# STM32H562 register map
File version: 0.1
CPU: CM33 r0p0, little endian, MPU, FPU, 4 interrupt priority bits
Registers are 32-bit, read-write, reset 0x0 unless marked. A register's access mark holds for its fields unless they carry their own. Offsets are from the block's base; [hi:lo] are bit positions; <NAME> marks a mode.

## SPI1 — Serial peripheral interface
Base 0x40013000
Same registers: SPI2 0x40003800, SPI3 0x40003C00, SPI4 0x40014C00, SPI6 0x40015000, SPI5 0x44002000, SEC_SPI2 0x50003800, SEC_SPI3 0x50003C00, SEC_SPI1 0x50013000, SEC_SPI4 0x50014C00, SEC_SPI6 0x50015000, SEC_SPI5 0x54002000
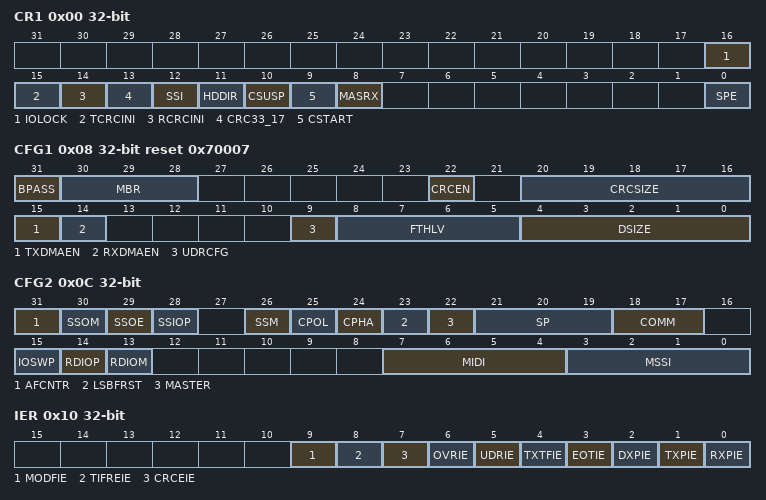
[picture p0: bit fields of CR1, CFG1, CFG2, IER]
0x00 CR1 access per field — SPI/I2S control register 1
  [16] IOLOCK rw — locking the AF configuration of associated IOs This bit is set by software and cleared by hardware whenever the SPE bit is changed from 1 to 0. When this bit is set, SPI_CFG2 register content cannot be modified. This bit can be set when SPI is disabled only else it is write protected. It is cleared and cannot be set when MODF bit is set.
  [15] TCRCINI rw — CRC calculation initialization pattern control for transmitter
  [14] RCRCINI rw — CRC calculation initialization pattern control for receiver
  [13] CRC33_17 rw — 32-bit CRC polynomial configuration
  [12] SSI rw — internal SS signal input level This bit has an effect only when the SSM bit is set. The value of this bit is forced onto the peripheral SS input internally and the I/O value of the SS pin is ignored.
  [11] HDDIR rw — Rx/Tx direction at Half-duplex mode In Half-Duplex configuration the HDDIR bit establishes the Rx/Tx direction of the data transfer. This bit is ignored in Full-Duplex or any Simplex configuration.
  [10] CSUSP wo — master SUSPend request This bit reads as zero. In Master mode, when this bit is set by software, the CSTART bit is reset at the end of the current frame and communication is suspended. The user has to check SUSP flag to check end of the frame transaction. The Master mode communication must be suspended (using this bit or keeping TXDR empty) before going to Low-power mode. Can be used in SPI or I2S mode. After software suspension, SUSP flag has to be cleared and SPI disabled and re-enabled before the next transaction starts.
  [9] CSTART rw — master transfer start This bit can be set by software if SPI is enabled only to start an SPI or I2S/PCM communication. In SPI mode, it is cleared by hardware when end of transfer (EOT) flag is set or when a transaction suspend request is accepted. In I2S/PCM mode, it is also cleared by hardware as described in the . In SPI mode, the bit is taken into account at master mode only. If transmission is enabled, communication starts or continues only if any data is available in the transmission FIFO.
  [8] MASRX rw — master automatic suspension in Receive mode This bit is set and cleared by software to control continuous SPI transfer in master receiver mode and automatic management in order to avoid overrun condition. When SPI communication is suspended by hardware automatically, it could happen that few bits of next frame are already clocked out due to internal synchronization delay. This is why, the automatic suspension is not quite reliable when size of data drops below 8 bits. In this case, a safe suspension can be achieved by combination with delay inserted between data frames applied when MIDI parameter keeps a non zero value; sum of data size and the interleaved SPI cycles should always produce interval at length of 8 SPI clock periods at minimum. After software clearing of the SUSP bit, the communication resumes and continues by subsequent bits transaction without any next constraint. Prior the SUSP bit is cleared, the user must release the RxFIFO space as much as possible by reading out all the data packets available at RxFIFO based on the RXP flag indication to prevent any subsequent suspension.
  [0] SPE rw — serial peripheral enable This bit is set by and cleared by software. When SPE=1, SPI data transfer is enabled, SPI_CFG1 and SPI_CFG2 configuration registers, CRCPOLY, UDRDR, IOLOCK bit in the SPI_CR1 register are write protected. They can be changed only when SPE=0. When SPE=0 any SPI operation is stopped and disabled, all the pending requests of the events with enabled interrupt are blocked except the MODF interrupt request (but their pending still propagates the request of the spi_plck clock), the SS output is deactivated at master, the RDY signal keeps not ready status at slave, the internal state machine is reseted, all the FIFOs content is flushed, CRC calculation initialized, receive data register is read zero. SPE is cleared and cannot be set when MODF error flag is active.
0x04 CR2 — SPI/I2S control register 2
  [15:0] TSIZE — number of data at current transfer When these bits are changed by software, the SPI has to be disabled. Endless transaction is initialized when CSTART is set while zero value is stored at TSIZE. TSIZE cannot be set to 0xFFFF respective 0x3FFF value when CRC is enabled. Note: TSIZE[15:10] bits are reserved at limited feature set instances and must be kept at reset value.
0x08 CFG1 reset 0x70007 — SPI/I2S configuration register 1
  [31] BPASS — bypass of the prescaler at master baud rate clock generator
  [30:28] MBR — master baud rate prescaler setting Note: MBR setting is considered at slave working at TI mode, too (see mode).
  [22] CRCEN — hardware CRC computation enable
  [20:16] CRCSIZE — length of CRC frame to be transacted and compared Most significant bits are taken into account from polynomial calculation when CRC result is transacted or compared. The length of the polynomial is not affected by this setting. ..... The value must be set equal or multiply of data size (DSIZE[4:0]). Its maximum size corresponds to DSIZE maximum at the instance. Note: The most significant bit at CRCSIZE bit field is reserved at the peripheral instances where data size is limited to 16-bit.
  [15] TXDMAEN — Tx DMA stream enable
  [14] RXDMAEN — Rx DMA stream enable
  [9] UDRCFG — behavior of slave transmitter at underrun condition For more details see underrun condition.
  [8:5] FTHLV — FIFO threshold level Defines number of data frames at single data packet. Size of the packet should not exceed 1/2 of FIFO space. SPI interface is more efficient if configured packet sizes are aligned with data register access parallelism: If SPI data register is accessed as a 16-bit register and DSIZE ≤ 8 bit, better to select FTHLV = 2, 4, 6. If SPI data register is accessed as a 32-bit register and DSIZE> 8 bit, better to select FTHLV = 2, 4, 6, while if DSIZE ≤ 8bit, better to select FTHLV = 4, 8, 12. Note: FTHLV[3:2] bits are reserved at instances with limited set of features
  [4:0] DSIZE — number of bits in at single SPI data frame ..... Note: Maximum data size can be limited up to 16-bits at some instances. At instances with limited set of features, DSIZE2:0] bits are reserved and must be kept at reset state. DSIZE[4:3] bits then control next settings of data size: 00xxx: 8-bits 01xxx: 16-bits 10xxx: 24-bits 11xxx: 32-bits.
0x0C CFG2 — SPI/I2S configuration register 2
  [31] AFCNTR — alternate function GPIOs control This bit is taken into account when SPE=0 only When SPI has to be disabled temporary for a specific configuration reason (e.g. CRC reset, CPHA or HDDIR change) setting this bit prevents any glitches on the associated outputs configured at alternate function mode by keeping them forced at state corresponding the current SPI configuration. Note: This bit can be also used in PCM and I2S modes. Note: The bit AFCNTR must not be set to 1, when the block is in slave mode.
  [30] SSOM — SS output management in Master mode This bit is taken into account in Master mode when SSOE is enabled. It allows the SS output to be configured between two consecutive data transfers.
  [29] SSOE — SS output enable This bit is taken into account in Master mode only
  [28] SSIOP — SS input/output polarity
  [26] SSM — software management of SS signal input When master uses hardware SS output (SSM=0 and SSOE=1) the SS signal input is forced to not active state internally to prevent master mode fault error.
  [25] CPOL — clock polarity
  [24] CPHA — clock phase
  [23] LSBFRST — data frame format Note: This bit can be also used in PCM and I2S modes.
  [22] MASTER — SPI Master
  [21:19] SP — serial protocol others: reserved, must not be used
  [18:17] COMM — SPI Communication Mode
  [15] IOSWP — swap functionality of MISO and MOSI pins When this bit is set, the function of MISO and MOSI pins alternate functions are inverted. Original MISO pin becomes MOSI and original MOSI pin becomes MISO. Note: This bit can be also used in PCM and I2S modes to swap SDO and SDI pins.
  [14] RDIOP — RDY signal input/output polarity
  [13] RDIOM — RDY signal input/output management Note: When DSIZE at the SPI_CFG1 register is configured shorter than 8-bit, the RDIOM bit has to be kept at zero.
  [7:4] MIDI — master Inter-Data Idleness Specifies minimum time delay (expressed in SPI clock cycles periods) inserted between two consecutive data frames in Master mode. ... Note: This feature is not supported in TI mode.
  [3:0] MSSI — Master SS Idleness Specifies an extra delay, expressed in number of SPI clock cycle periods, inserted additionally between active edge of SS opening a session and the beginning of the first data frame of the session in Master mode when SSOE is enabled. ... Note: This feature is not supported in TI mode. To include the delay, the SPI must be disabled and re-enabled between sessions.
0x10 IER — SPI/I2S interrupt enable register
  [9] MODFIE — mode Fault interrupt enable
  [8] TIFREIE — TIFRE interrupt enable
  [7] CRCEIE — CRC error interrupt enable
  [6] OVRIE — OVR interrupt enable
  [5] UDRIE — UDR interrupt enable
  [4] TXTFIE — TXTFIE interrupt enable
  [3] EOTIE — EOT, SUSP and TXC interrupt enable
  [2] DXPIE — DXP interrupt enabled DXPIE is set by software and cleared by TXTF flag set event.
  [1] TXPIE — TXP interrupt enable TXPIE is set by software and cleared by TXTF flag set event.
  [0] RXPIE — RXP interrupt enable
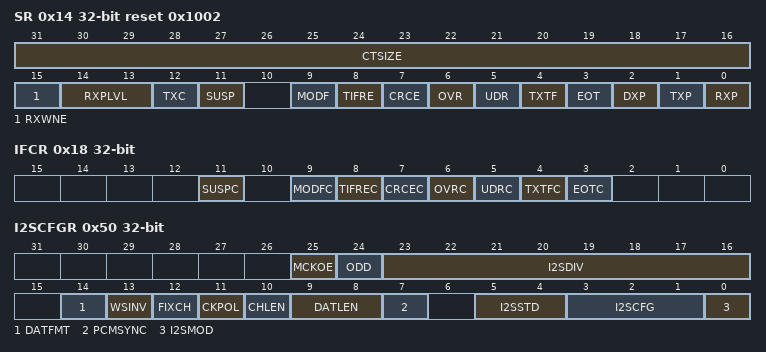
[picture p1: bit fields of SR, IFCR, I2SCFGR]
0x14 SR ro reset 0x1002 — SPI/I2S status register
  [31:16] CTSIZE — number of data frames remaining in current TSIZE session The value is not quite reliable when traffic is ongoing on bus or during autonomous operation in low-power mode. Note: CTSIZE[15:0] bits are not available in instances with limited set of features.
  [15] RXWNE — RxFIFO word not empty Note: This bit value does not depend on DSIZE setting and keeps together with RXPLVL[1:0] information about RxFIFO occupancy by residual data.
  [14:13] RXPLVL — RxFIFO packing level When RXWNE=0 and data size is set up to 16-bit, the value gives number of remaining data frames persisting at RxFIFO. Note: (*): Optional value when data size is set up to 8-bit only. When data size is greater than 16-bit, these bits are always read as 00. In that consequence, the single data frame received at the FIFO cannot be detected neither by RWNE nor by RXPLVL bits if data size is set from 17 to 24 bits. The user then must apply other methods like TSIZE>0 or FTHLV=0.
  [12] TXC — TxFIFO transmission complete The flag behavior depends on TSIZE setting. When TSIZE=0 the TXC is changed by hardware exclusively and it raises each time the TxFIFO becomes empty and there is no activity on the bus. If TSIZE <>0 there is no specific reason to monitor TXC as it just copies the EOT flag value including its software clearing. The TXC generates an interrupt when EOTIE is set.
  [11] SUSP — suspension status In Master mode, SUSP is set by hardware either as soon as the current frame is completed after CSUSP request is done or at master automatic suspend receive mode (MASRX bit is set at SPI_CR1 register) on RxFIFO full condition. SUSP generates an interrupt when EOTIE is set. This bit has to be cleared prior SPI is disabled and this is done by writing 1 to SUSPC bit of SPI_IFCR exclusively.
  [9] MODF — mode fault This bit is cleared by writing 1 to MODFC bit of SPI_IFCR exclusively.
  [8] TIFRE — TI frame format error This bit is cleared by writing 1 to TIFREC bit of SPI_IFCR exclusively.
  [7] CRCE — CRC error This bit is cleared when SPI is re-enabled or by writing 1 to CRCEC bit of SPI_IFCR optionally.
  [6] OVR — overrun This bit is cleared when SPI is re-enabled or by writing 1 to OVRC bit of SPI_IFCR optionally.
  [5] UDR — underrun This bit is cleared when SPI is re-enabled or by writing 1 to UDRC bit of SPI_IFCR optionally. Note: In SPI mode, the UDR flag applies to Slave mode only. In I2S/PCM mode, (when available) this flag applies to Master and Slave mode
  [4] TXTF — transmission transfer filled TXTF is set by hardware as soon as all of the data packets in a transfer have been submitted for transmission by application software or DMA, that is when TSIZE number of data have been pushed into the TxFIFO. This bit is cleared by software write 1 to TXTFC bit of SPI_IFCR exclusively. TXTF flag triggers an interrupt if TXTFIE bit is set. TXTF setting clears the TXPIE and DXPIE masks so to off-load application software from calculating when to disable TXP and DXP interrupts.
  [3] EOT — end of transfer EOT is set by hardware as soon as a full transfer is complete, that is when SPI is re-enabled or when TSIZE number of data have been transmitted and/or received on the SPI. EOT is cleared when SPI is re-enabled or by writing 1 to EOTC bit of SPI_IFCR optionally. EOT flag triggers an interrupt if EOTIE bit is set. If DXP flag is used until TXTF flag is set and DXPIE is cleared, EOT can be used to download the last packets contained into RxFIFO in one-shot. In master, EOT event terminates the data transaction and handles SS output optionally. When CRC is applied, the EOT event is extended over the CRC frame transaction. To restart the internal state machine properly, SPI is strongly suggested to be disabled and re-enabled before next transaction starts despite its setting is not changed.
  [2] DXP — duplex packet DXP flag is set whenever both TXP and RXP flags are set regardless SPI mode.
  [1] TXP — Tx-Packet space available In I2S mode, it must be interpreted as follow: there is less than FTHLV free locations in the TxFIFO In I2S mode, it must be interpreted as follow: there is FTHLV or more than FTHLV free locations in the TxFIFO TXP flag is changed by hardware. It monitors overall space currently available at TxFIFO no matter if SPI is enabled or not. It has to be checked once a complete data packet is stored at TxFIFO.
  [0] RXP — Rx-Packet available In I2S mode, it must be interpreted as follow: RxFIFO level is lower than FTHLV In I2S mode, it must be interpreted as follow: RxFIFO level is higher or equal to FTHLV RXP flag is changed by hardware. It monitors number of overall data currently available at RxFIFO if SPI is enabled. It has to be checked once a data packet is completely read out from RxFIFO.
0x18 IFCR wo — SPI/I2S interrupt/status flags clear register
  [11] SUSPC — SUSPend flag clear Writing a 1 into this bit clears SUSP flag in the SPI_SR register
  [9] MODFC — mode fault flag clear Writing a 1 into this bit clears MODF flag in the SPI_SR register
  [8] TIFREC — TI frame format error flag clear Writing a 1 into this bit clears TIFRE flag in the SPI_SR register
  [7] CRCEC — CRC error flag clear Writing a 1 into this bit clears CRCE flag in the SPI_SR register
  [6] OVRC — overrun flag clear Writing a 1 into this bit clears OVR flag in the SPI_SR register
  [5] UDRC — underrun flag clear Writing a 1 into this bit clears UDR flag in the SPI_SR register
  [4] TXTFC — transmission transfer filled flag clear Writing a 1 into this bit clears TXTF flag in the SPI_SR register
  [3] EOTC — end of transfer flag clear Writing a 1 into this bit clears EOT flag in the SPI_SR register
0x20 TXDR wo — SPI/I2S transmit data register
  [31:0] TXDR — transmit data register The register serves as an interface with TxFIFO. A write to it accesses TxFIFO. Note: In SPI mode, data is always right-aligned. Alignment of data at I2S mode depends on DATLEN and DATFMT setting. Unused bits are ignored when writing to the register, and read as zero when the register is read. Note: DR can be accessed byte-wise (8-bit access): in this case only one data-byte is written by single access. halfword-wise (16 bit access) in this case 2 data-bytes or 1 halfword-data can be written by single access. word-wise (32 bit access). In this case 4 data-bytes or 2 halfword-data or word-data can be written by single access. Write access of this register less than the configured data size is forbidden.
0x30 RXDR ro — SPI/I2S receive data register
  [31:0] RXDR — receive data register The register serves as an interface with RxFIFO. When it is read, RxFIFO is accessed. Note: In SPI mode, data is always right-aligned. Alignment of data at I2S mode depends on DATLEN and DATFMT setting. Unused bits are read as zero when the register is read. Writing to the register is ignored. Note: DR can be accessed byte-wise (8-bit access): in this case only one data-byte is read by single access halfword-wise (16 bit access) in this case 2 data-bytes or 1 halfword-data can be read by single access word-wise (32 bit access). In this case 4 data-bytes or 2 halfword-data or word-data can be read by single access. Read access of this register less than the configured data size is forbidden.
0x40 CRCPOLY reset 0x107 — SPI/I2S polynomial register
  [31:0] CRCPOLY — CRC polynomial register This register contains the polynomial for the CRC calculation. The default 9-bit polynomial setting 0x107 corresponds to default 8-bit setting of DSIZE. It is compatible with setting 0x07 used at some other ST products with fixed length of the polynomial string where the most significant bit of the string is always kept hidden. Length of the polynomial is given by the most significant bit of the value stored at this register. It has to be set greater than DSIZE. CRC33_17 bit has to be set additionally with CRCPOLY register when DSIZE is configured to maximum 32-bit or 16-bit size and CRC is enabled (to keep polynomial length grater than data size). Note: CRCPOLY[31:16] bits are reserved at instances with data size limited to 16-bit. There is no constrain when 32-bit access is applied at these addresses. Reserved bits 31-16 are always read zero while any write to them is ignored.
0x44 TXCRC ro — SPI/I2S transmitter CRC register
  [31:0] TXCRC — CRC register for transmitter When CRC calculation is enabled, the TXCRC[31:0] bits contain the computed CRC value of the subsequently transmitted bytes. CRC calculation is initialized when the CRCEN bit of SPI_CR1 is written to 1 or when a data block is transacted completely. The CRC is calculated serially using the polynomial programmed in the SPI_CRCPOLY register. The number of bits considered at calculation depends on SPI_CRCPOLY register and CRCSIZE bits settings at SPI_CFG1 register. Note: a read to this register when the communication is ongoing could return an incorrect value. Note: not used for the I2S mode. Note: TXCRC[31-16] bits are reserved at instances with data size limited to 16-bit. There is no constrain when 32-bit access is applied at these addresses. Reserved bits 31-16 are always read zero while any write to them is ignored. Note: The configuration of CRCSIZE bit field is not taken into account when the content of this register is read by software. No masking is applied for unused bits at this case.
0x48 RXCRC ro — SPI/I2S receiver CRC register
  [31:0] RXCRC — CRC register for receiver When CRC calculation is enabled, the RXCRC[31:0] bits contain the computed CRC value of the subsequently received bytes. CRC calculation is initialized when the CRCEN bit of SPI_CR1 is written to 1 or when a data block is transacted completely. The CRC is calculated serially using the polynomial programmed in the SPI_CRCPOLY register. The number of bits considered at calculation depends on SPI_CRCPOLY register and CRCSIZE bits settings at SPI_CFG1 register. Note: a read to this register when the communication is ongoing could return an incorrect value. Not used for the I2S mode. RXCRC[31-16] bits are reserved at the peripheral instances with data size limited to 16-bit. There is no constrain when 32-bit access is applied at these addresses. Reserved bits 31-16 are always read zero while any write to them is ignored. Note: The configuration of CRCSIZE bit field is not taken into account when the content of this register is read by software. No masking is applied for unused bits at this case.
0x4C UDRDR — SPI/I2S underrun data register
  [31:0] UDRDR — data at slave underrun condition The register is taken into account in Slave mode and at underrun condition only. The number of bits considered depends on DSIZE bit settings of the SPI_CFG1 register. Underrun condition handling depends on setting UDRCFG bit at SPI_CFG1 register. Note: UDRDR[31-16] bits are reserved at the peripheral instances with data size limited to 16-bit. There is no constraint when 32-bit access is applied at these addresses. Reserved bits 31-16 are always read zero while any write to them is ignored.
0x50 I2SCFGR — SPI/I2S configuration register
  [25] MCKOE — master clock output enable
  [24] ODD — odd factor for the prescaler Refer to for details
  [23:16] I2SDIV — I2S linear prescaler I2SDIV can take any values except the value 1, when ODD is also equal to 1. Refer to for details
  [14] DATFMT — data format
  [13] WSINV — word select inversion This bit is used to invert the default polarity of WS signal. WS is LOW. In PCM mode the start of frame is indicated by a rising edge. WS is HIGH. In PCM mode the start of frame is indicated by a falling edge.
  [12] FIXCH — fixed channel length in slave
  [11] CKPOL — serial audio clock polarity
  [10] CHLEN — channel length (number of bits per audio channel)
  [9:8] DATLEN — data length to be transferred
  [7] PCMSYNC — PCM frame synchronization
  [5:4] I2SSTD — I2S standard selection For more details on I2S standards, refer to
  [3:1] I2SCFG — I2S configuration mode others, not used
  [0] I2SMOD — I2S mode selection
